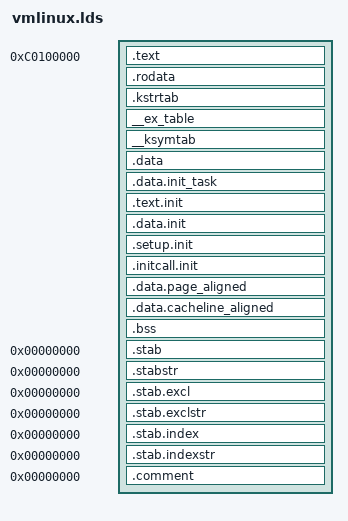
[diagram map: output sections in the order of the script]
/* ld script to make i386 Linux kernel
 * Written by Martin Mares <mj@atrey.karlin.mff.cuni.cz>;
 */
OUTPUT_FORMAT("elf32-i386", "elf32-i386", "elf32-i386")
OUTPUT_ARCH(i386)
ENTRY(_start)
SECTIONS
{
  . = 0xC0000000 + 0x100000;
  _text = .;			/* Text and read-only data */
  .text : {
	*(.text)
	*(.fixup)
	*(.gnu.warning)
	} = 0x9090

  _etext = .;			/* End of text section */

  .rodata : { *(.rodata) *(.rodata.*) }
  .kstrtab : { *(.kstrtab) }

  . = ALIGN(16);		/* Exception table */
  __start___ex_table = .;
  __ex_table : { *(__ex_table) }
  __stop___ex_table = .;

  __start___ksymtab = .;	/* Kernel symbol table */
  __ksymtab : { *(__ksymtab) }
  __stop___ksymtab = .;

  .data : {			/* Data */
	*(.data)
	CONSTRUCTORS
	}

  _edata = .;			/* End of data section */

  . = ALIGN(8192);		/* init_task */
  .data.init_task : { *(.data.init_task) }

  . = ALIGN(4096);		/* Init code and data */
  __init_begin = .;
  .text.init : { *(.text.init) }
  .data.init : { *(.data.init) }
  . = ALIGN(16);
  __setup_start = .;
  .setup.init : { *(.setup.init) }
  __setup_end = .;
  __initcall_start = .;
  .initcall.init : { *(.initcall.init) }
  __initcall_end = .;
  . = ALIGN(4096);
  __init_end = .;

  . = ALIGN(4096);
  .data.page_aligned : { *(.data.idt) }

  . = ALIGN(32);
  .data.cacheline_aligned : { *(.data.cacheline_aligned) }

  __bss_start = .;		/* BSS */
  .bss : {
	*(.bss)
	}
  _end = . ;

  /* Sections to be discarded */
  /DISCARD/ : {
	*(.text.exit)
	*(.data.exit)
	*(.exitcall.exit)
	}

  /* Stabs debugging sections.  */
  .stab 0 : { *(.stab) }
  .stabstr 0 : { *(.stabstr) }
  .stab.excl 0 : { *(.stab.excl) }
  .stab.exclstr 0 : { *(.stab.exclstr) }
  .stab.index 0 : { *(.stab.index) }
  .stab.indexstr 0 : { *(.stab.indexstr) }
  .comment 0 : { *(.comment) }
}
